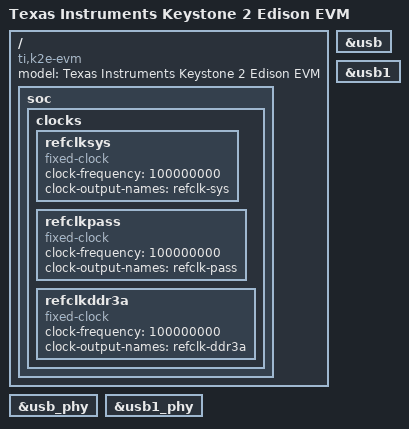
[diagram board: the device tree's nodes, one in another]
/*
 * Copyright 2013-2014 Texas Instruments, Inc.
 *
 * Keystone 2 Edison EVM device tree
 *
 * This program is free software; you can redistribute it and/or modify
 * it under the terms of the GNU General Public License version 2 as
 * published by the Free Software Foundation.
 */
/dts-v1/;

#include "keystone.dtsi"
#include "k2e.dtsi"

/ {
	compatible =  "ti,k2e-evm","ti,keystone";
	model = "Texas Instruments Keystone 2 Edison EVM";

	soc {

		clocks {
			refclksys: refclksys {
				#clock-cells = <0>;
				compatible = "fixed-clock";
				clock-frequency = <100000000>;
				clock-output-names = "refclk-sys";
			};

			refclkpass: refclkpass {
				#clock-cells = <0>;
				compatible = "fixed-clock";
				clock-frequency = <100000000>;
				clock-output-names = "refclk-pass";
			};

			refclkddr3a: refclkddr3a {
				#clock-cells = <0>;
				compatible = "fixed-clock";
				clock-frequency = <100000000>;
				clock-output-names = "refclk-ddr3a";
			};
		};
	};
};

&usb_phy {
	status = "okay";
};

&usb {
	status = "okay";
};

&usb1_phy {
	status = "okay";
};

&usb1 {
	status = "okay";
};
